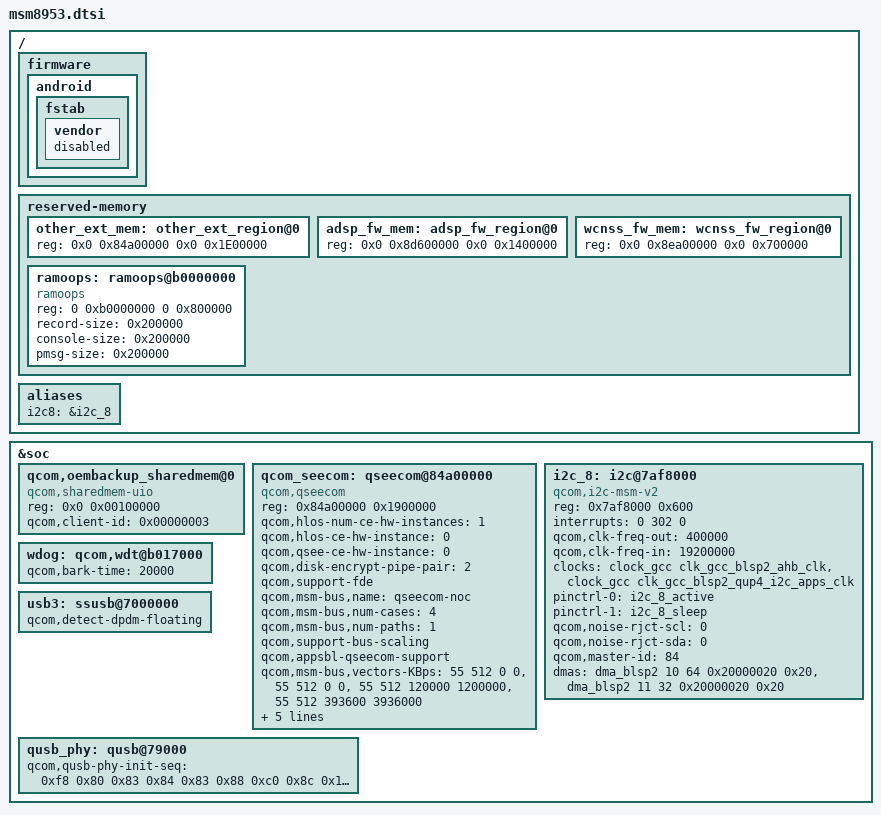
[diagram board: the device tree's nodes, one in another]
/*
 * Copyright (c) 2015-2019, The Linux Foundation. All rights reserved.
 *
 * This program is free software; you can redistribute it and/or modify
 * it under the terms of the GNU General Public License version 2 and
 * only version 2 as published by the Free Software Foundation.
 *
 * This program is distributed in the hope that it will be useful,
 * but WITHOUT ANY WARRANTY; without even the implied warranty of
 * MERCHANTABILITY or FITNESS FOR A PARTICULAR PURPOSE.  See the
 * GNU General Public License for more details.
 */

/ {
	firmware: firmware {
		android {
			/delete-node/ vbmeta;

			fstab {
				vendor {
					status = "disable";
				};
			};
		};
	};

	reserved-memory {
		other_ext_mem: other_ext_region@0 {
			reg = <0x0 0x84a00000 0x0 0x1E00000>;
		};

		adsp_fw_mem: adsp_fw_region@0 {
			reg = <0x0 0x8d600000 0x0 0x1400000>;
		};

		wcnss_fw_mem: wcnss_fw_region@0 {
			reg = <0x0 0x8ea00000 0x0 0x700000>;
		};

		ramoops: ramoops@b0000000 {
			compatible = "ramoops";
			reg = <0 0xb0000000 0 0x800000>;
			record-size = <0x200000>;
			console-size = <0x200000>;
			pmsg-size = <0x200000>;
		};
	};

	aliases {
		/delete-property/ spi3;
		i2c8 = &i2c_8;
	};
};

&soc {
	/delete-node/ spi@78b7000;

	qcom,oembackup_sharedmem@0 {
		compatible = "qcom,sharedmem-uio";
		reg = <0x0 0x00100000>; /* '0' indicates dynamic allocation */
		reg-names = "oembackup";
		qcom,client-id = <0x00000003>;
	};

	/delete-node/ qseecom@85b00000;
	qcom_seecom: qseecom@84a00000 {
		compatible = "qcom,qseecom";
		reg = <0x84a00000 0x1900000>;
		reg-names = "secapp-region";
		qcom,hlos-num-ce-hw-instances = <1>;
		qcom,hlos-ce-hw-instance = <0>;
		qcom,qsee-ce-hw-instance = <0>;
		qcom,disk-encrypt-pipe-pair = <2>;
		qcom,support-fde;
		qcom,msm-bus,name = "qseecom-noc";
		qcom,msm-bus,num-cases = <4>;
		qcom,msm-bus,num-paths = <1>;
		qcom,support-bus-scaling;
		qcom,appsbl-qseecom-support;
		qcom,msm-bus,vectors-KBps =
			<55 512 0 0>,
			<55 512 0 0>,
			<55 512 120000 1200000>,
			<55 512 393600 3936000>;
		clocks = <&clock_gcc clk_crypto_clk_src>,
			 <&clock_gcc clk_gcc_crypto_clk>,
			 <&clock_gcc clk_gcc_crypto_ahb_clk>,
			 <&clock_gcc clk_gcc_crypto_axi_clk>;
		clock-names = "core_clk_src", "core_clk",
				"iface_clk", "bus_clk";
		qcom,ce-opp-freq = <100000000>;
		status = "okay";
	};

	i2c_8: i2c@7af8000 { /* BLSP2 QUP4 */
		compatible = "qcom,i2c-msm-v2";
		#address-cells = <1>;
		#size-cells = <0>;
		reg-names = "qup_phys_addr";
		reg = <0x7af8000 0x600>;
		interrupt-names = "qup_irq";
		interrupts = <0 302 0>;
		qcom,clk-freq-out = <400000>;
		qcom,clk-freq-in  = <19200000>;
		clock-names = "iface_clk", "core_clk";
		clocks = <&clock_gcc clk_gcc_blsp2_ahb_clk>,
			 <&clock_gcc clk_gcc_blsp2_qup4_i2c_apps_clk>;

		pinctrl-names = "i2c_active", "i2c_sleep";
		pinctrl-0 = <&i2c_8_active>;
		pinctrl-1 = <&i2c_8_sleep>;
		qcom,noise-rjct-scl = <0>;
		qcom,noise-rjct-sda = <0>;
		qcom,master-id = <84>;
		dmas = <&dma_blsp2 10 64 0x20000020 0x20>,
			<&dma_blsp2 11 32 0x20000020 0x20>;
		dma-names = "tx", "rx";
		status = "okay";
	};

	wdog: qcom,wdt@b017000 {
		qcom,bark-time = <20000>;
	};

	usb3: ssusb@7000000{
		qcom,detect-dpdm-floating;
	};

	qusb_phy: qusb@79000 {
		qcom,qusb-phy-init-seq = <0xf8 0x80
					0x83 0x84
					0x83 0x88
					0xc0 0x8c
					0x14 0x9c
					0x30 0x08
					0x79 0x0c
					0x21 0x10
					0x00 0x90
					0x9f 0x1c
					0x00 0x18>;
	};
};
